VERSION ""

NS_ :

BS_:

BU_: Dashboard MotorController SensorNode

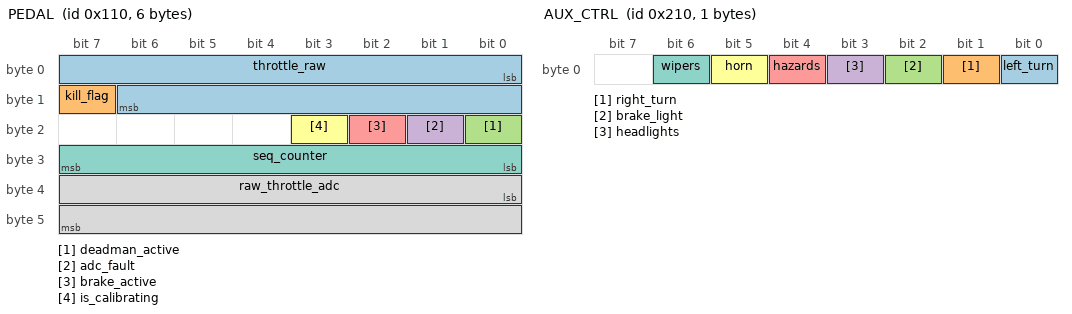
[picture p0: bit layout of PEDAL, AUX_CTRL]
BO_ 272 PEDAL: 6 MotorController
 SG_ throttle_raw : 0|15@1+ (1,0) [0|32767] ""  Dashboard
 SG_ kill_flag : 15|1@1+ (1,0) [0|1] ""  Dashboard
 SG_ deadman_active : 16|1@1+ (1,0) [0|1] ""  Dashboard
 SG_ adc_fault : 17|1@1+ (1,0) [0|1] ""  Dashboard
 SG_ brake_active : 18|1@1+ (1,0) [0|1] ""  Dashboard
 SG_ is_calibrating : 19|1@1+ (1,0) [0|1] ""  Dashboard
 SG_ seq_counter : 24|8@1+ (1,0) [0|255] ""  Dashboard
 SG_ raw_throttle_adc : 32|16@1+ (1,0) [0|65535] ""  Dashboard

BO_ 528 AUX_CTRL: 1 SensorNode
 SG_ left_turn : 0|1@1+ (1,0) [0|1] ""  Dashboard
 SG_ right_turn : 1|1@1+ (1,0) [0|1] ""  Dashboard
 SG_ brake_light : 2|1@1+ (1,0) [0|1] ""  Dashboard
 SG_ headlights : 3|1@1+ (1,0) [0|1] ""  Dashboard
 SG_ hazards : 4|1@1+ (1,0) [0|1] ""  Dashboard
 SG_ horn : 5|1@1+ (1,0) [0|1] ""  Dashboard
 SG_ wipers : 6|1@1+ (1,0) [0|1] ""  Dashboard

BO_ 784 PWR_MONITOR_780: 4 SensorNode
 SG_ volts : 0|16@1+ (0.003125,0) [0|204.8] "V"  Dashboard
 SG_ amps : 16|16@1- (0.0024,0) [-78.64|78.64] "A"  Dashboard

BO_ 785 PWR_MONITOR_740: 4 SensorNode
 SG_ volts : 0|16@1+ (0.003125,0) [0|204.8] "V"  Dashboard
 SG_ amps : 16|16@1- (0.0012,0) [-39.32|39.32] "A"  Dashboard

BO_ 786 PWR_ENERGY: 5 SensorNode
 SG_ energy_joules : 0|40@1+ (0.00768,0) [0|8446744073] "J"  Dashboard

BO_ 1024 DASH_STAT: 8 Dashboard
 SG_ data : 0|64@1+ (1,0) [0|1.844674407E+019] ""  MotorController

CM_ "DBC file auto-generated from legacy can_payloads.h";
